# M00_SystolicArray register map
Vendor: Babel; File version: 1.0
M00_SystolicArray Register Map
CPU: CM0 r0p0, little endian, no MPU, no FPU
Registers are 32-bit, read-write, reset 0x0 unless marked. A register's access mark holds for its fields unless they carry their own. Offsets are from the block's base; lines under a group give offsets from that group; [hi:lo] are bit positions; {n}, {i} and the like mark numbered series; 'fields as' and 'values as' point back to an identical list; <NAME> marks a mode.

## Memory map
0x00000000 M00_SystolicArray

## M00_SystolicArray
Base 0x00000000
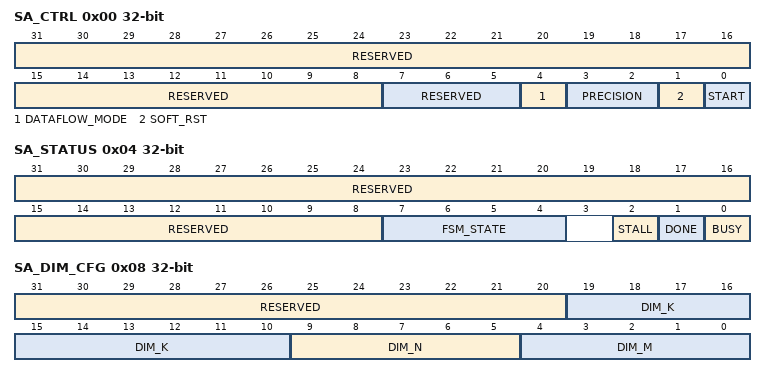
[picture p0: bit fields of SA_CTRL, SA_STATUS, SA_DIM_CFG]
0x00 SA_CTRL — 控制寄存器：start、soft_rst、precision、dataflow_mode
  [31:8] RESERVED - — 保留，必须写 0
  [7:5] RESERVED - — 保留，必须写 0
  [4] DATAFLOW_MODE — 数据流模式。0=output-stationary, 1=weight-stationary
  [3:2] PRECISION — 精度选择。00=INT8, 01=FP16, 10=BF16
  [1] SOFT_RST — 软复位。写 1 触发内部复位，自清零
  [0] START — 启动计算。写 1 启动，完成后自动清零
0x04 SA_STATUS ro — 状态寄存器：busy、done、stall、fsm_state
  [31:8] RESERVED - — 保留
  [7:4] FSM_STATE — 当前 FSM 状态编码
  [2] STALL — 停顿标志。1=数据通路停顿
  [1] DONE — 完成标志。1=上次计算完成
  [0] BUSY — 忙标志。1=正在计算
0x08 SA_DIM_CFG — 矩阵维度配置：dim_m、dim_n、dim_k
  [31:20] RESERVED - — 保留，必须写 0
  [19:10] DIM_K — 矩阵 K 维度 (0-1023)
  [9:5] DIM_N — 矩阵 N 维度 (0-31)
  [4:0] DIM_M — 矩阵 M 维度 (0-31)
0x0C SA_PERF_CNT ro — 计算周期计数器（每次 start 清零）
  [31:0] COUNT — 计算周期计数。每次 START 清零
